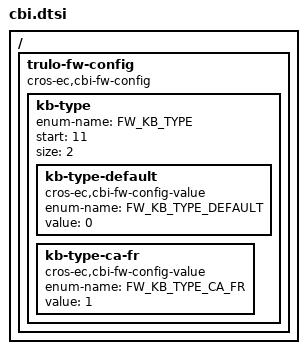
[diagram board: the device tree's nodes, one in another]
/* Copyright 2024 The ChromiumOS Authors
 * Use of this source code is governed by a BSD-style license that can be
 * found in the LICENSE file.
 */

/ {
	/* Trulo-specific fw_config fields. */
	trulo-fw-config {
		compatible = "cros-ec,cbi-fw-config";
		/*
		 * FW_CONFIG field to change scancode setting for special
		 * keyboard type.
		 */
		kb-type {
			enum-name = "FW_KB_TYPE";
			start = <11>;
			size = <2>;

			kb-type-default {
				compatible = "cros-ec,cbi-fw-config-value";
				enum-name = "FW_KB_TYPE_DEFAULT";
				value = <0>;
			};
			kb-type-ca-fr {
				compatible = "cros-ec,cbi-fw-config-value";
				enum-name = "FW_KB_TYPE_CA_FR";
				value = <1>;
			};
		};
	};
};
